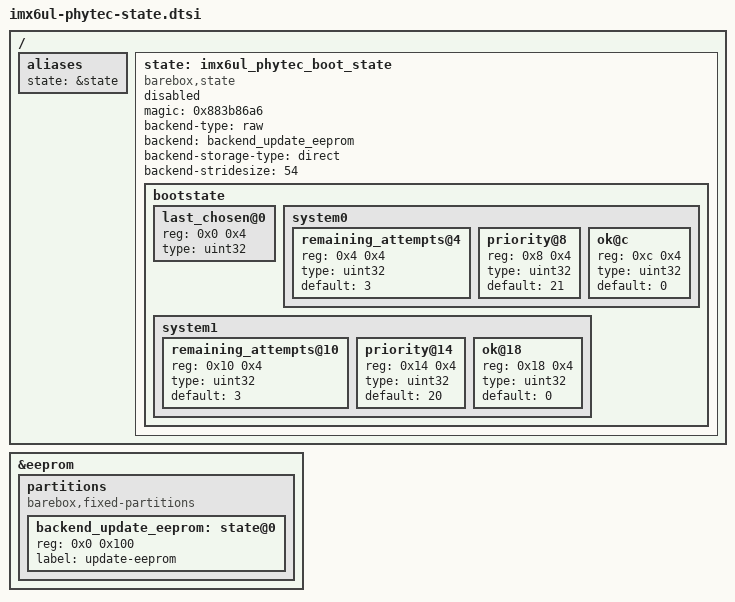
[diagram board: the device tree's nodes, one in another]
// SPDX-License-Identifier: (GPL-2.0+ OR MIT)
/*
 * Copyright (C) 2019 PHYTEC Messtechnik GmbH,
 * Author: Stefan Riedmueller <s.riedmueller@phytec.de>
 */

/ {
	aliases {
		state = &state;
	};

	state: imx6ul_phytec_boot_state {
		magic = <0x883b86a6>;
		compatible = "barebox,state";
		backend-type = "raw";
		backend = <&backend_update_eeprom>;
		backend-storage-type = "direct";
		backend-stridesize = <54>;
		status = "disabled";

		bootstate {
			#address-cells = <1>;
			#size-cells = <1>;
			last_chosen@0 {
				reg = <0x0 0x4>;
				type = "uint32";
			};
			system0 {
				#address-cells = <1>;
				#size-cells = <1>;
				remaining_attempts@4 {
					reg = <0x4 0x4>;
					type = "uint32";
					default = <3>;
				};
				priority@8 {
					reg = <0x8 0x4>;
					type = "uint32";
					default = <21>;
				};
				ok@c {
					reg = <0xc 0x4>;
					type = "uint32";
					default = <0>;
				};
			};
			system1 {
				#address-cells = <1>;
				#size-cells = <1>;
				remaining_attempts@10 {
					reg = <0x10 0x4>;
					type = "uint32";
					default = <3>;
				};
				priority@14 {
					reg = <0x14 0x4>;
					type = "uint32";
					default = <20>;
				};
				ok@18 {
					reg = <0x18 0x4>;
					type = "uint32";
					default = <0>;
				};
			};
		};
	};
};

&eeprom {
	partitions {
		compatible = "barebox,fixed-partitions";
		#size-cells = <1>;
		#address-cells = <1>;
		backend_update_eeprom: state@0 {
			reg = <0x0 0x100>;
			label = "update-eeprom";
		};
	};
};
